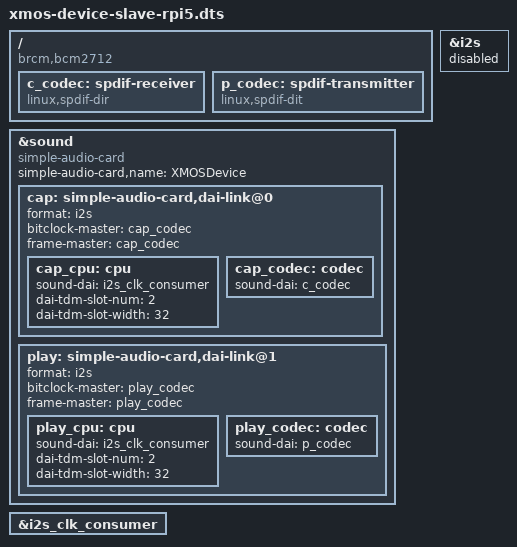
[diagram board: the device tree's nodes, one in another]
// Device tree overlay for XMOS I2S audio devices — RPi 5 as I2S clock consumer
//
// This overlay is for configurations where the XVF3800 provides BCLK/LRCLK
// (i.e., XVF3800 is the I2S master). Uses the i2s_clk_consumer controller
// which is only available on Raspberry Pi 5 (BCM2712).
//
// RPi 5 has separate I2S controllers for master (i2s / i2s_clk_producer)
// and slave (i2s_clk_consumer). The default &i2s node is master-only and
// will reject slave clock configurations with -EINVAL.
//
// See: https://github.com/raspberrypi/linux/issues/5724
//
// For RPi 4, use xmos-device-slave.dts instead.
/dts-v1/;
/plugin/;

/ {
    // 2712 for RPi 5
    compatible = "brcm,bcm2712";

    fragment@0 {
        target = <&sound>;
        __overlay__ {
            compatible = "simple-audio-card";
            simple-audio-card,name = "XMOSDevice";
            status = "okay";

            // Capture
            cap: simple-audio-card,dai-link@0 {
                format = "i2s";

                // XVF3800 as master (RPi as slave)
                bitclock-master = <&cap_codec>;
                frame-master = <&cap_codec>;

                cap_cpu: cpu {
                    sound-dai = <&i2s_clk_consumer>;

                    // Stereo
                    dai-tdm-slot-num = <2>;
                    // 32-Bit
                    dai-tdm-slot-width = <32>;
                };

                cap_codec: codec {
                    sound-dai = <&c_codec>;
                };
            };

            // Playback
            play: simple-audio-card,dai-link@1 {
                format = "i2s";

                // XVF3800 as master (RPi as slave)
                bitclock-master = <&play_codec>;
                frame-master = <&play_codec>;

                play_cpu: cpu {
                    sound-dai = <&i2s_clk_consumer>;

                    // Stereo
                    dai-tdm-slot-num = <2>;
                    // 32-Bit
                    dai-tdm-slot-width = <32>;
                };

                play_codec: codec {
                    sound-dai = <&p_codec>;
                };
            };
        };
    };

    fragment@1 {
        target-path = "/";
        __overlay__ {
            // Uses S/PDIF codec as a generic I2S driver.
            c_codec: spdif-receiver {
                compatible = "linux,spdif-dir";
                status = "okay";
                #address-cells = <0>;
                #size-cells = <0>;
                #sound-dai-cells = <0>;
            };

            p_codec: spdif-transmitter {
                compatible = "linux,spdif-dit";
                status = "okay";
                #address-cells = <0>;
                #size-cells = <0>;
                #sound-dai-cells = <0>;
            };
        };
    };

    // Enable the slave I2S controller
    fragment@2 {
        target = <&i2s_clk_consumer>;
        __overlay__ {
            status = "okay";
            #sound-dai-cells = <0>;
        };
    };

    // Disable the master I2S controller to prevent pin conflict
    fragment@3 {
        target = <&i2s>;
        __overlay__ {
            status = "disabled";
        };
    };
};
